# bcp register map
Vendor: Texas Instruments
Peripheral module from a debugger description file (folder Keystone2).
Registers are 32-bit, read-only, no defined reset value unless marked. A register's access mark holds for its fields unless they carry their own. Offsets are as the file gives them; lines under a group give offsets from that group; [hi:lo] are bit positions; {n}, {i} and the like mark numbered series; 'fields as' and 'values as' point back to an identical list; <NAME> marks a mode.

## BCP
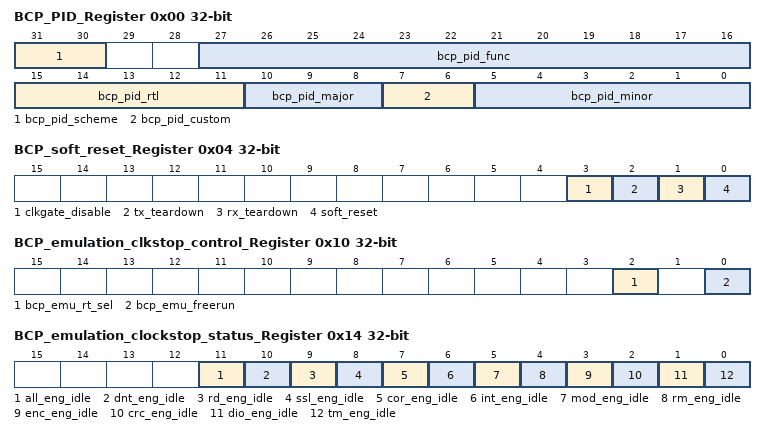
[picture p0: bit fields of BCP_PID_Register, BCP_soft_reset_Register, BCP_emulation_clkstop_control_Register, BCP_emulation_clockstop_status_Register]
0x00 BCP_PID_Register
  [31:30] bcp_pid_scheme, [27:16] bcp_pid_func, [15:11] bcp_pid_rtl, [10:8] bcp_pid_major, [7:6] bcp_pid_custom, [5:0] bcp_pid_minor
0x04 BCP_soft_reset_Register access per field
  [3] clkgate_disable rw — Disables PPB clock gating when set
  [2] tx_teardown rw — TX goes into teardown when set
  [1] rx_teardown rw — RX goes into teardown when set
  [0] soft_reset wo — Resets BCP when set to a 1
0x08 TM_Halt_Ctrl_Register wo — TM halt control register
  [7:0] clear_halt — Clears a halt condition on a channel
0x0C TM_Halt_status_Register
  [7:0] halt_status — Status of halt on a channel
0x10 BCP_emulation_clkstop_control_Register rw — BCP Emulation control register
  [2] bcp_emu_rt_sel — Use dbgsusp_rt when high, dbgsusp when low
  [0] bcp_emu_freerun — Emulation mode is free running when set
0x14 BCP_emulation_clockstop_status_Register — BCP emulation and clockstop status
  [11] all_eng_idle — All engines are idle when bit is set.
  [10] dnt_eng_idle — DNT engine is idle when bit is set.
  [9] rd_eng_idle — RD engine is idle when bit is set.
  [8] ssl_eng_idle — SSL engine is idle when bit is set.
  [7] cor_eng_idle — COR engine is idle when bit is set.
  [6] int_eng_idle — INT engine is idle when bit is set.
  [5] mod_eng_idle — MOD engine is idle when bit is set.
  [4] rm_eng_idle — RM engine is idle when bit is set.
  [3] enc_eng_idle — ENC engine is idle when bit is set.
  [2] crc_eng_idle — CRC engine is idle when bit is set.
  [1] dio_eng_idle — DIO engine is idle when bit is set.
  [0] tm_eng_idle — TM engine is idle when bit is set.
0x18 BCP_datalogger_SW_timestamp_Register rw — BCP Datalogger Software Timestamp
  [31:0] bcp_dlg_sw_timestamp — Datalogger software timestamp.
0x1C BCP_datalogger_HW_timestamp_Register — BCP Datalogger Hardware Timestamp
  [23:0] bcp_dlg_hw_timestamp — Datalogger hardware timestamp.
0x20 BCP_datalogger_HW_timestamp_ctrl_Register rw — BCP Datalogger Hardware Timestamp ctrl
  [0] bcp_dlg_hw_timestamp_run — Datalogger hardware timestamp ctrl.
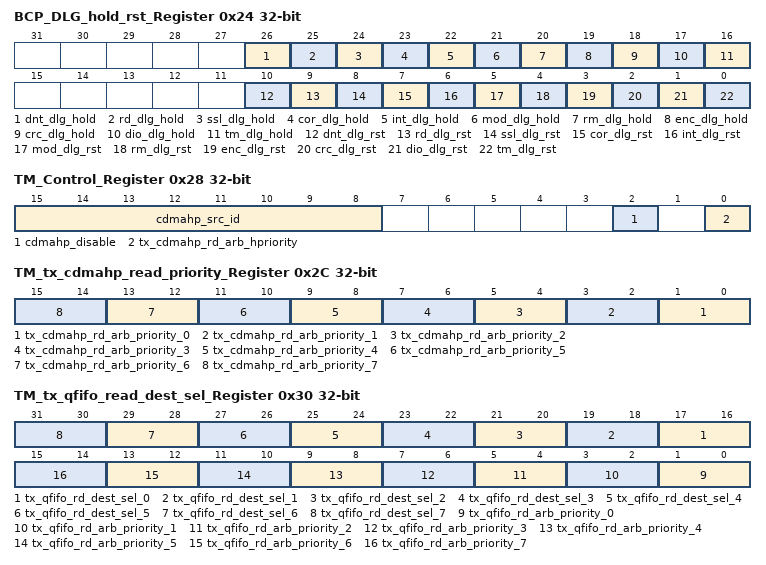
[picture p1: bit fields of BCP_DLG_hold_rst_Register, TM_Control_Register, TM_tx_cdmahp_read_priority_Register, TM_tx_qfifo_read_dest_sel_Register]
0x24 BCP_DLG_hold_rst_Register rw
  [26] dnt_dlg_hold — DNT Data logger put into DLG_HOLD state to hold DLG values when set
  [25] rd_dlg_hold — RD Data logger put into DLG_HOLD state to hold DLG values when set
  [24] ssl_dlg_hold — SSL Data logger put into DLG_HOLD state to hold DLG values when set
  [23] cor_dlg_hold — COR Data logger put into DLG_HOLD state to hold DLG values when set
  [22] int_dlg_hold — INT Data logger put into DLG_HOLD state to hold DLG values when set
  [21] mod_dlg_hold — MOD Data logger put into DLG_HOLD state to hold DLG values when set
  [20] rm_dlg_hold — RM Data logger put into DLG_HOLD state to hold DLG values when set
  [19] enc_dlg_hold — ENC Data logger put into DLG_HOLD state to hold DLG values when set
  [18] crc_dlg_hold — CRC Data logger put into DLG_HOLD state to hold DLG values when set
  [17] dio_dlg_hold — DIO Data logger put into DLG_HOLD state to hold DLG values when set
  [16] tm_dlg_hold — TM Data logger put into DLG_HOLD state to hold DLG values when set
  [10] dnt_dlg_rst — DNT Data logger put into DLG_IDLE state to reset DLG when set
  [9] rd_dlg_rst — RD Data logger put into DLG_IDLE state to reset DLG when set
  [8] ssl_dlg_rst — SSL Data logger put into DLG_IDLE state to reset DLG when set
  [7] cor_dlg_rst — COR Data logger put into DLG_IDLE state to reset DLG when set
  [6] int_dlg_rst — INT Data logger put into DLG_IDLE state to reset DLG when set
  [5] mod_dlg_rst — MOD Data logger put into DLG_IDLE state to reset DLG when set
  [4] rm_dlg_rst — RM Data logger put into DLG_IDLE state to reset DLG when set
  [3] enc_dlg_rst — ENC Data logger put into DLG_IDLE state to reset DLG when set
  [2] crc_dlg_rst — CRC Data logger put into DLG_IDLE state to reset DLG when set
  [1] dio_dlg_rst — DIO Data logger put into DLG_IDLE state to reset DLG when set
  [0] tm_dlg_rst — TM Data logger put into DLG_IDLE state to reset DLG when set
0x28 TM_Control_Register rw
  [15:8] cdmahp_src_id — SRC_ID to insert into RX INFO word 0.
  [2] cdmahp_disable — Disables inputs from the CDMAHP when set high.
  [0] tx_cdmahp_rd_arb_hpriority — Enables increasing tx rd arb priority while that packetis being transferred.
0x2C TM_tx_cdmahp_read_priority_Register rw
  [2n+1:2n] tx_cdmahp_rd_arb_priority_{n} (n=0..7) — Sets CDMAHP read priority for channel {n}.
0x30 TM_tx_qfifo_read_dest_sel_Register rw — TM TX QFIFO read dest sel and arbitrtion priority register
  [2n+17:2n+16] tx_qfifo_rd_dest_sel_{n} (n=0..7) — Sets QFIFO read dest select for channel {n}.
  [2n+1:2n] tx_qfifo_rd_arb_priority_{n} (n=0..7) — Sets QFIFO read arbitration priority for channel {n}.
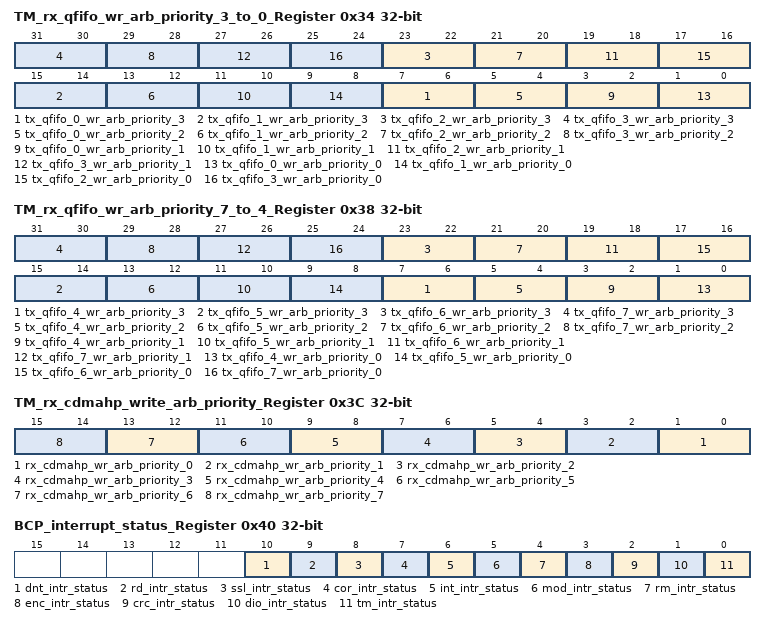
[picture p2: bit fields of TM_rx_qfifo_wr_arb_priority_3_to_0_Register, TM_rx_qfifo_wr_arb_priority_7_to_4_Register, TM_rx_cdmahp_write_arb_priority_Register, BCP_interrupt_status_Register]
0x34 TM_rx_qfifo_wr_arb_priority_3_to_0_Register rw — TM RX QFIFO write arb priority register for channels 0 to 3
  [8n+7:8n+6] tx_qfifo_{n}_wr_arb_priority_3 (n=0..3) — Sets QFIFO {n} wr arb priority from PPB 3.
  [8n+5:8n+4] tx_qfifo_{n}_wr_arb_priority_2 (n=0..3) — Sets QFIFO {n} wr arb priority from PPB 2.
  [8n+3:8n+2] tx_qfifo_{n}_wr_arb_priority_1 (n=0..3) — Sets QFIFO {n} wr arb priority from PPB 1.
  [8n+1:8n] tx_qfifo_{n}_wr_arb_priority_0 (n=0..3) — Sets QFIFO {n} wr arb priority from PPB 0.
0x38 TM_rx_qfifo_wr_arb_priority_7_to_4_Register rw — TM RX QFIFO write arb priority register for channels 7 to 4
  [8n-25:8n-26] tx_qfifo_{n}_wr_arb_priority_3 (n=4..7) — Sets QFIFO {n} wr arb priority from PPB 3.
  [8n-27:8n-28] tx_qfifo_{n}_wr_arb_priority_2 (n=4..7) — Sets QFIFO {n} wr arb priority from PPB 2.
  [8n-29:8n-30] tx_qfifo_{n}_wr_arb_priority_1 (n=4..7) — Sets QFIFO {n} wr arb priority from PPB 1.
  [8n-31:8n-32] tx_qfifo_{n}_wr_arb_priority_0 (n=4..7) — Sets QFIFO {n} wr arb priority from PPB 0.
0x3C TM_rx_cdmahp_write_arb_priority_Register rw
  [2n+1:2n] rx_cdmahp_wr_arb_priority_{n} (n=0..7) — Sets CDMAHP write priority for channel {n}.
0x40 BCP_interrupt_status_Register — (1 of 4, stride 8)
  [10] dnt_intr_status — DNT engine is interrupting when bit is set.
  [9] rd_intr_status — RD engine is interrupting when bit is set.
  [8] ssl_intr_status — SSL engine is interrupting when bit is set.
  [7] cor_intr_status — COR engine is interrupting when bit is set.
  [6] int_intr_status — INT engine is interrupting when bit is set.
  [5] mod_intr_status — MOD engine is interrupting when bit is set.
  [4] rm_intr_status — RM engine is interrupting when bit is set.
  [3] enc_intr_status — ENC engine is interrupting when bit is set.
  [2] crc_intr_status — CRC engine is interrupting when bit is set.
  [1] dio_intr_status — DIO engine is interrupting when bit is set.
  [0] tm_intr_status — TM engine is interrupting when bit is set.
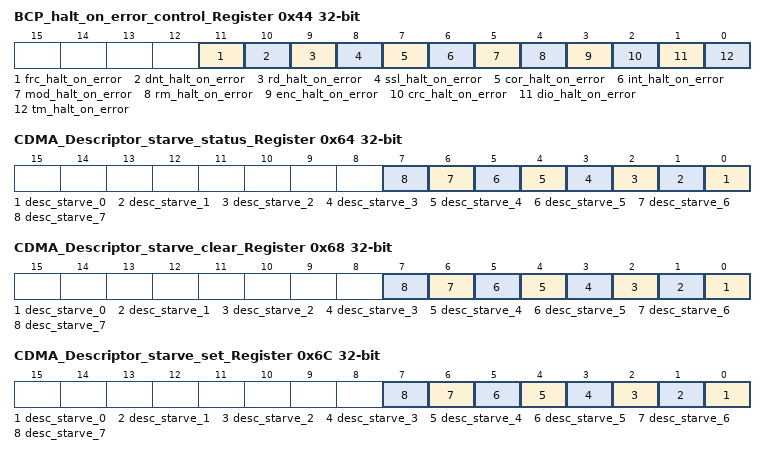
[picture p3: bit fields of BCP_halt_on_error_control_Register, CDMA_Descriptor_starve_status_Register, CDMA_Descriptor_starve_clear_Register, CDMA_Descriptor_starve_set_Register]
0x44 BCP_halt_on_error_control_Register rw — (1 of 4, stride 8)
  [11] frc_halt_on_error — Halts TM.
  [10] dnt_halt_on_error — Halts TM on an error from the DNT engine.
  [9] rd_halt_on_error — Halts TM on an error from the RD engine.
  [8] ssl_halt_on_error — Halts TM on an error from the SSL engine.
  [7] cor_halt_on_error — Halts TM on an error from the COR engine.
  [6] int_halt_on_error — Halts TM on an error from the INT engine.
  [5] mod_halt_on_error — Halts TM on an error from the MOD engine.
  [4] rm_halt_on_error — Halts TM on an error from the RM engine.
  [3] enc_halt_on_error — Halts TM on an error from the ENC engine.
  [2] crc_halt_on_error — Halts TM on an error from the CRC engine.
  [1] dio_halt_on_error — Halts TM on an error from the DIO engine.
  [0] tm_halt_on_error — Halts TM on an error from the TM engine.
0x60 BCP_EOI_Register rw
  [7:0] bcp_eoi — BCP EOI vector for all interrupts.
0x64 CDMA_Descriptor_starve_status_Register — CDMAHP Descriptor Starve status register
  [n] desc_starve_{n} (n=0..7) — CDMAHP descriptor starve indication for queue {n}.
0x68 CDMA_Descriptor_starve_clear_Register wo — CDMAHP Descriptor Starve Clear register
  [n] desc_starve_{n} (n=0..7) — CDMAHP descriptor starve clear for queue {n}.
0x6C CDMA_Descriptor_starve_set_Register wo — CDMAHP Descriptor Starve Set register
  [n] desc_starve_{n} (n=0..7) — CDMAHP descriptor starve set for queue {n}.
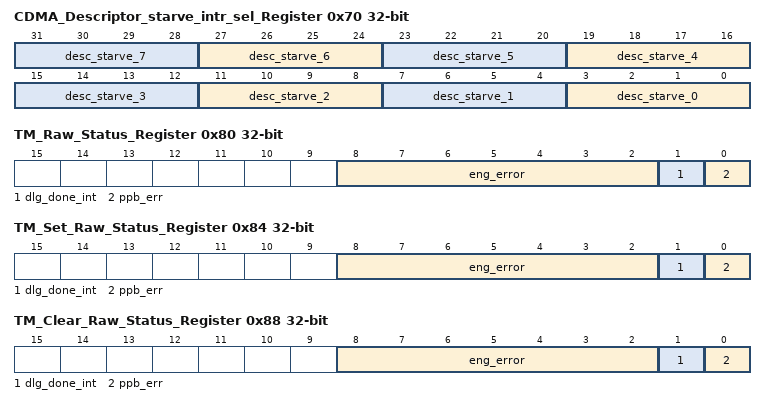
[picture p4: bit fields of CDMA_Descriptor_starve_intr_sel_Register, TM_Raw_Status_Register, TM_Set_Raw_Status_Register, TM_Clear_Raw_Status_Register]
0x70 CDMA_Descriptor_starve_intr_sel_Register rw — CDMAHP Descriptor Starve intr sel register
  [4n+3:4n] desc_starve_{n} (n=0..7) — CDMAHP descriptor starve interrupt CPU selection for queue {n}.
0x80 TM_Raw_Status_Register — (1 of 4, stride 28)
  [8:2] eng_error
  [1] dlg_done_int — data logger Error.
  [0] ppb_err — PPB Error.
0x84 TM_Set_Raw_Status_Register wo — (1 of 4, stride 28)
  [8:2] eng_error — Set Engine errors.
  [1] dlg_done_int — Set Data logger done has ocurred.
  [0] ppb_err — Set PPB Error.
0x88 TM_Clear_Raw_Status_Register wo — (1 of 4, stride 28)
  [8:2] eng_error — Clear Engine errors.
  [1] dlg_done_int — Clear Data logger done has ocurred.
  [0] ppb_err — Clear PPB Error.
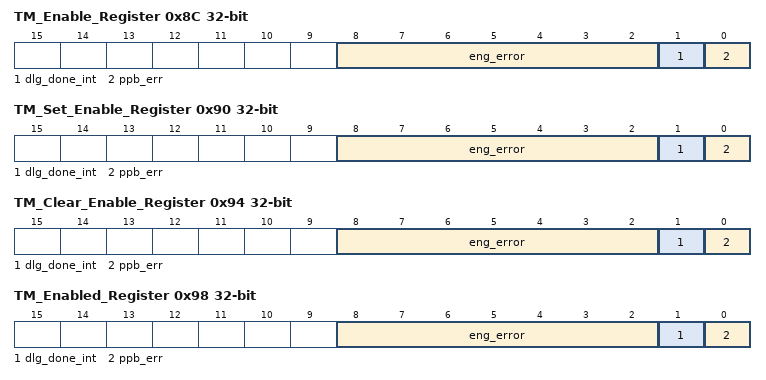
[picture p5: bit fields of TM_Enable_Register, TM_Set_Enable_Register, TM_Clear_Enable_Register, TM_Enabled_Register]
0x8C TM_Enable_Register — (1 of 4, stride 28)
  [8:2] eng_error — Set Engine errors.
  [1] dlg_done_int — Set Data logger done has ocurred.
  [0] ppb_err — Enable for PPB Error.
0x90 TM_Set_Enable_Register wo — (1 of 4, stride 28)
  [8:2] eng_error — Set Enable Engine errors.
  [1] dlg_done_int — Set Enable Data logger done has ocurred.
  [0] ppb_err — Set Enable PPB Error.
0x94 TM_Clear_Enable_Register wo — (1 of 4, stride 28)
  [8:2] eng_error — Clear Enable Engine errors.
  [1] dlg_done_int — Clear Enable Data logger done has ocurred.
  [0] ppb_err — Clear Enable PPB Error.
0x98 TM_Enabled_Register — (1 of 4, stride 28)
  [8:2] eng_error — Set Engine errors.
  [1] dlg_done_int — Set Data logger done has ocurred.
  [0] ppb_err — Enabled PPB Error.
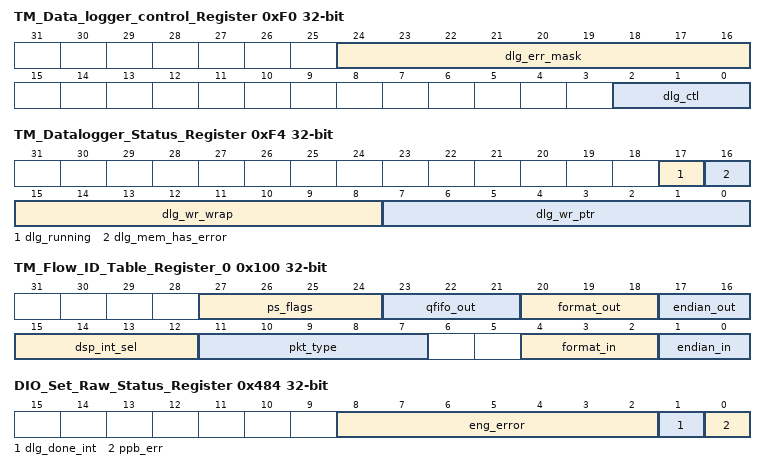
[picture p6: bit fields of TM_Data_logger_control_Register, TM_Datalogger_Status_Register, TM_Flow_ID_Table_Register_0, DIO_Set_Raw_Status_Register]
0xF0 TM_Data_logger_control_Register rw — Data logger control Register
  [24:16] dlg_err_mask — Masks off the corresponding error field to the DLG when set.
  [2:0] dlg_ctl — Selects the mode that DLG is running. Shown in the datalogger write control section.
0xF4 TM_Datalogger_Status_Register — Datalogger Status Register
  [17] dlg_running — Set while capturing data.
  [16] dlg_mem_has_error — At least one error is stored in memory.
  [15:8] dlg_wr_wrap — Number of times writing to memory wrapped to 0. Stops at FF
  [7:0] dlg_wr_ptr — Read only passing the current RAM write pointer.
0xF8 TM_Global_Header_Register
  [31:0] global_hdr — Read only passing the current value of the Global Header field.
0x100 TM_Flow_ID_Table_Register_0 rw — (1 of 64, stride 4)
  [27:24] ps_flags — PS_FLAGS to set for RX INFO word 0.
  [23:21] qfifo_out — Selects which QFIFO in the RX the PPB sends the data through.
  [20:18] format_out — Format going out of the RX for payload.
  [17:16] endian_out — Endian going out of the RX for payload.
  [15:12] dsp_int_sel — Interrupt Select for which DSP to interrupt on errors.
  [11:7] pkt_type — Packet type for RX INFO word 0.
  [4:2] format_in — format coming in to TX for payload.
  [1:0] endian_in — Endian coming in to TX for payload
0x400 DIO_Vbusm_Priority rw — BCP DIO Vbusm priority Register
  [2:0] dio_vbusm_priority — Controls priority outputs from the dio core.0x0 is highest priority, 0x7 is lowest priority
0x480 DIO_Raw_Status_Register — (1 of 4, stride 28)
  [7:0] ppb_err — PPB Error.
0x484 DIO_Set_Raw_Status_Register wo — (1 of 4, stride 28)
  fields as TM_Set_Raw_Status_Register
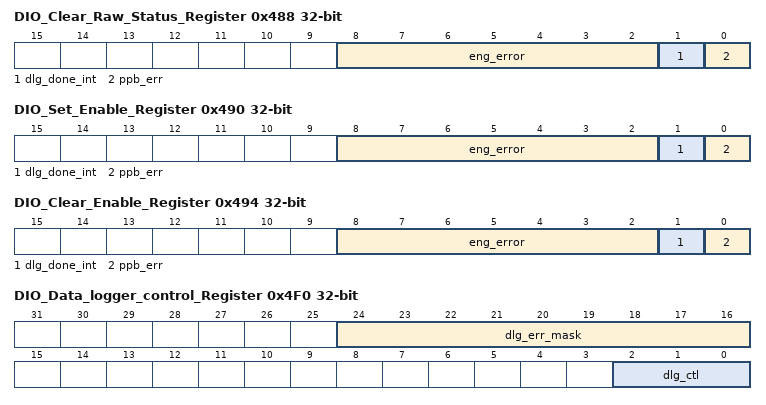
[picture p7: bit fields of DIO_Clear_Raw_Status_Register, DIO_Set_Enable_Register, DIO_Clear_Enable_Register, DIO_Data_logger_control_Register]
0x488 DIO_Clear_Raw_Status_Register wo — (1 of 4, stride 28)
  fields as TM_Clear_Raw_Status_Register
0x48C DIO_Enable_Register — (1 of 4, stride 28)
  [7:0] ppb_err — Enable for PPB Error.
0x490 DIO_Set_Enable_Register wo — (1 of 4, stride 28)
  fields as TM_Set_Enable_Register
0x494 DIO_Clear_Enable_Register wo — (1 of 4, stride 28)
  fields as TM_Clear_Enable_Register
0x498 DIO_Enabled_Register — (1 of 4, stride 28)
  [7:0] ppb_err — Enabled PPB Error.
0x4F0 DIO_Data_logger_control_Register rw — Data logger control Register
  fields as TM_Data_logger_control_Register
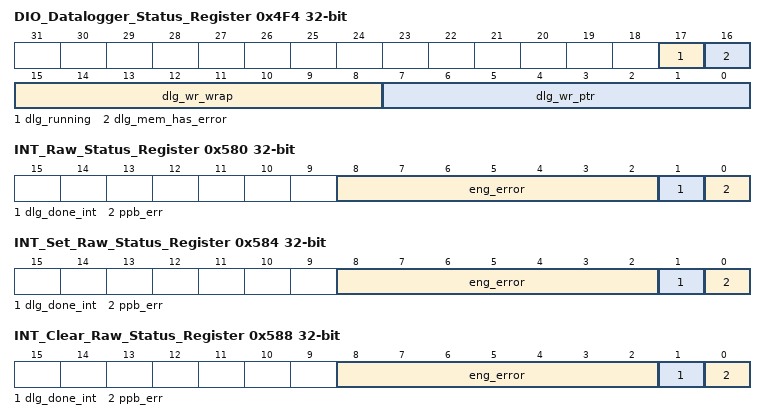
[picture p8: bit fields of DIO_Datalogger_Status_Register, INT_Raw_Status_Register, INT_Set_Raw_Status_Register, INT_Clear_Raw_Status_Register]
0x4F4 DIO_Datalogger_Status_Register — Datalogger Status Register
  fields as TM_Datalogger_Status_Register
0x4F8 DIO_Global_Header_Register — Submodule Global Header Register
  fields as TM_Global_Header_Register
0x580 INT_Raw_Status_Register — (1 of 4, stride 28)
  [8:2] eng_error — Engine errors.
  [1] dlg_done_int — Data logger done has ocurred.
  [0] ppb_err — PPB Error.
0x584 INT_Set_Raw_Status_Register wo — (1 of 4, stride 28)
  fields as TM_Set_Raw_Status_Register
0x588 INT_Clear_Raw_Status_Register wo — (1 of 4, stride 28)
  fields as TM_Clear_Raw_Status_Register
0x58C INT_Enable_Register — (1 of 4, stride 28)
  [8:2] eng_error — Enable for Engine errors.
  [1] dlg_done_int — Enable for Data logger done has ocurred.
  [7:0] ppb_err — Enable for PPB Error.
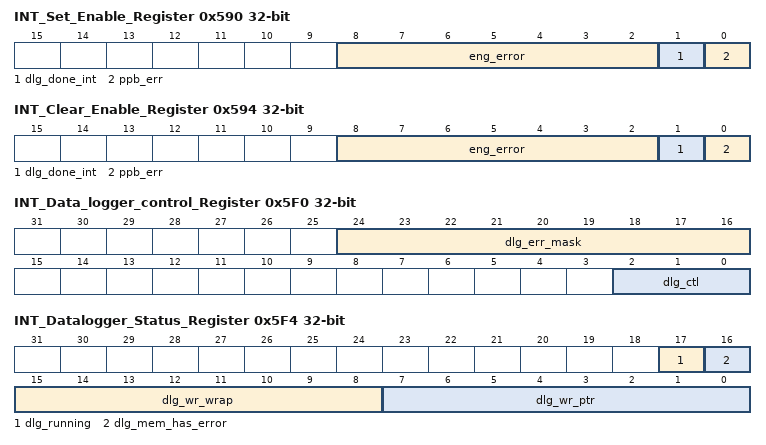
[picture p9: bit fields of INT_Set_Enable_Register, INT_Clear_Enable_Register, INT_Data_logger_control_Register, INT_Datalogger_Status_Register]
0x590 INT_Set_Enable_Register wo — (1 of 4, stride 28)
  fields as TM_Set_Enable_Register
0x594 INT_Clear_Enable_Register wo — (1 of 4, stride 28)
  fields as TM_Clear_Enable_Register
0x598 INT_Enabled_Register — (1 of 4, stride 28)
  [8:2] eng_error — Enabled Engine errors.
  [7:0] ppb_err — Enabled PPB Error.
0x5F0 INT_Data_logger_control_Register rw — Data logger control Register
  fields as TM_Data_logger_control_Register
0x5F4 INT_Datalogger_Status_Register — Datalogger Status Register
  fields as TM_Datalogger_Status_Register
0x5F8 INT_Global_Header_Register — Submodule Global Header Register
  fields as TM_Global_Header_Register
0x680 RM_Raw_Status_Register — (1 of 4, stride 28)
  [7:0] ppb_err — PPB Error.
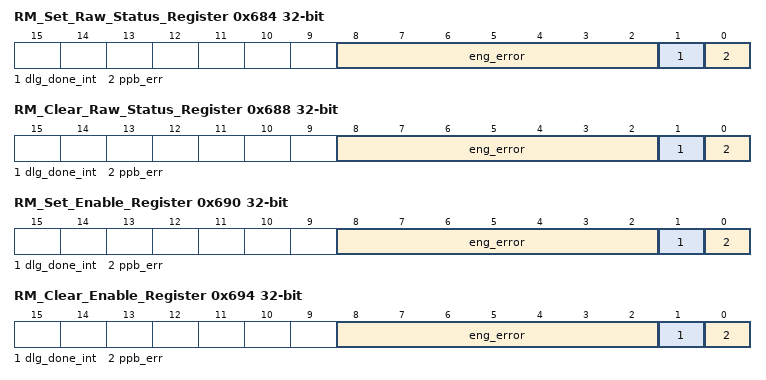
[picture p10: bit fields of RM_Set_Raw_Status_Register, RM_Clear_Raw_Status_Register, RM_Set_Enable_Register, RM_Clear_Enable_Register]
0x684 RM_Set_Raw_Status_Register wo — (1 of 4, stride 28)
  fields as TM_Set_Raw_Status_Register
0x688 RM_Clear_Raw_Status_Register wo — (1 of 4, stride 28)
  fields as TM_Clear_Raw_Status_Register
0x68C RM_Enable_Register — (1 of 4, stride 28)
  [7:0] ppb_err — Enable for PPB Error.
0x690 RM_Set_Enable_Register wo — (1 of 4, stride 28)
  fields as TM_Set_Enable_Register
0x694 RM_Clear_Enable_Register wo — (1 of 4, stride 28)
  fields as TM_Clear_Enable_Register
0x698 RM_Enabled_Register — (1 of 4, stride 28)
  [7:0] ppb_err — Enabled PPB Error.
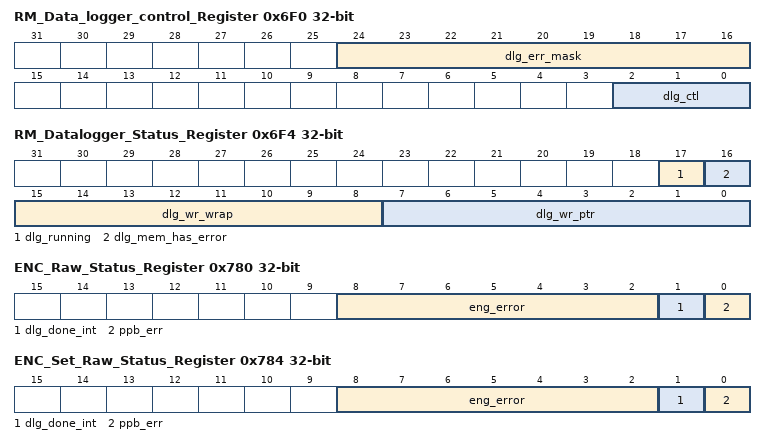
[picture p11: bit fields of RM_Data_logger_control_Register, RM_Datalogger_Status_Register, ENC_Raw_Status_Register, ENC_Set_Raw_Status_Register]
0x6F0 RM_Data_logger_control_Register rw — Data logger control Register
  fields as TM_Data_logger_control_Register
0x6F4 RM_Datalogger_Status_Register — Datalogger Status Register
  fields as TM_Datalogger_Status_Register
0x6F8 RM_Global_Header_Register
  fields as TM_Global_Header_Register
{0x6FC+4i} POLY_COEF{i} rw (i=1..3) — polynomial coefficient set {i}
  [23:0] POLYCOEF{i} — polynomial coefficients in 32-bit word as described in the specification (LSB Justified)
{0x70C+0x10*i} SCR_INIT_{i} rw (i=0..2) — scrambler initialization set {i}
  [31:16] SCRINIT — Scrambler Initialization (MSB justified)
{0x710+0x10*i} SCR_POLY_{i} rw (i=0..2) — scrambler Polynomial set {i}
  [31:16] SCRPOLY — Scrambler Polynomial (MSB justified)
0x714 CRC24_INIT_0 rw — CRC-24 Initialization set 0
  [31:8] CRC24INIT — CRC 24 Initialization (MSB justified)
0x718 CRC24_POLY_0 rw — CRC-24 Polynomial set 0
  [31:8] CRC24POLY — CRC 24 Polynomial (MSB justified)
0x724 CRC16_INIT_1 rw — CRC-16 Initialization set 1
  [31:16] CRC16INIT — CRC 16 Initialization (MSB justified)
0x728 CRC16_POLY_1 rw — CRC-16 Polynomial set 1
  [31:16] CRC16POLY — CRC 16 Polynomial (MSB justified)
0x780 ENC_Raw_Status_Register — (1 of 4, stride 28)
  fields as INT_Raw_Status_Register
0x784 ENC_Set_Raw_Status_Register wo — (1 of 4, stride 28)
  fields as TM_Set_Raw_Status_Register
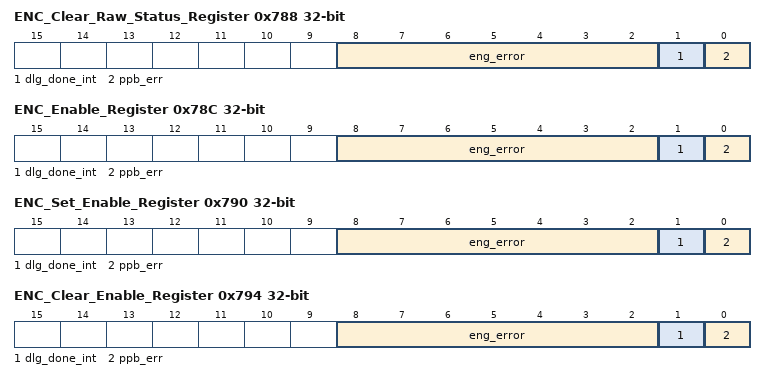
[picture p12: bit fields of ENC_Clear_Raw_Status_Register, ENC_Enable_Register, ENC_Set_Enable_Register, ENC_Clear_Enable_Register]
0x788 ENC_Clear_Raw_Status_Register wo — (1 of 4, stride 28)
  fields as TM_Clear_Raw_Status_Register
0x78C ENC_Enable_Register — (1 of 4, stride 28)
  [8:2] eng_error — Enable for Engine errors.
  [1] dlg_done_int — Enable for Data logger done .
  [0] ppb_err — Enable for PPB Error.
0x790 ENC_Set_Enable_Register wo — (1 of 4, stride 28)
  fields as TM_Set_Enable_Register
0x794 ENC_Clear_Enable_Register wo — (1 of 4, stride 28)
  fields as TM_Clear_Enable_Register
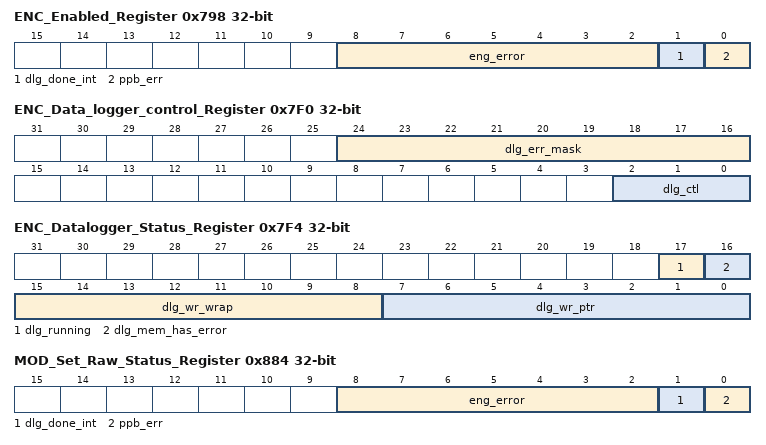
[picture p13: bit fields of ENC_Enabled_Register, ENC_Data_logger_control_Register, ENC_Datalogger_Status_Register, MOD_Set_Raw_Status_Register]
0x798 ENC_Enabled_Register — (1 of 4, stride 28)
  [8:2] eng_error — Enabled Engine errors.
  [1] dlg_done_int — Enabled Data logger done.
  [0] ppb_err — Enabled PPB Error.
0x7F0 ENC_Data_logger_control_Register rw — Data logger control Register
  fields as TM_Data_logger_control_Register
0x7F4 ENC_Datalogger_Status_Register — Datalogger Status Register
  fields as TM_Datalogger_Status_Register
0x7F8 ENC_Global_Header_Register — Submodule Global Header Register
  fields as TM_Global_Header_Register
0x880 MOD_Raw_Status_Register — (1 of 4, stride 28)
  [7:0] ppb_err — PPB Error.
0x884 MOD_Set_Raw_Status_Register wo — (1 of 4, stride 28)
  fields as TM_Set_Raw_Status_Register
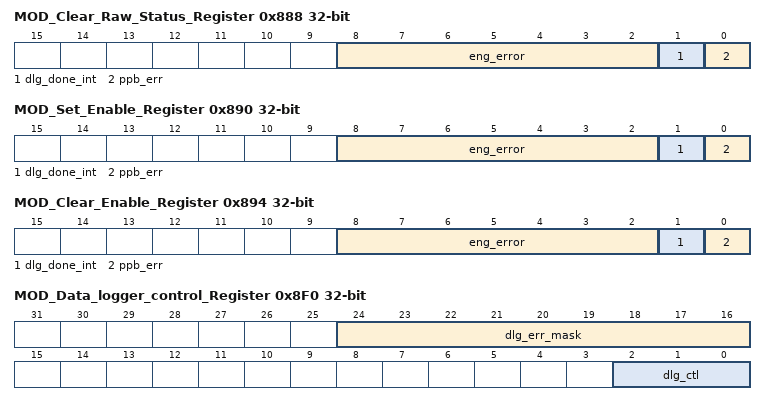
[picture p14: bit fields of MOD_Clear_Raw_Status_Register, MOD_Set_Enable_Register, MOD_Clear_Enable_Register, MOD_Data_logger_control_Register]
0x888 MOD_Clear_Raw_Status_Register wo — (1 of 4, stride 28)
  fields as TM_Clear_Raw_Status_Register
0x88C MOD_Enable_Register — (1 of 4, stride 28)
  [7:0] ppb_err — Enable for PPB Error.
0x890 MOD_Set_Enable_Register wo — (1 of 4, stride 28)
  fields as TM_Set_Enable_Register
0x894 MOD_Clear_Enable_Register wo — (1 of 4, stride 28)
  fields as TM_Clear_Enable_Register
0x898 MOD_Enabled_Register — (1 of 4, stride 28)
  [7:0] ppb_err — Enabled PPB Error.
0x8F0 MOD_Data_logger_control_Register rw — Data logger control Register
  fields as TM_Data_logger_control_Register
0x8F4 MOD_Datalogger_Status_Register — Datalogger Status Register
  fields as TM_Datalogger_Status_Register
0x8F8 MOD_Global_Header_Register — Submodule Global Header Register
  fields as TM_Global_Header_Register
0x980 DNT_Raw_Status_Register — (1 of 4, stride 28)
  fields as INT_Raw_Status_Register
0x984 DNT_Set_Raw_Status_Register wo — (1 of 4, stride 28)
  fields as TM_Set_Raw_Status_Register
0x988 DNT_Clear_Raw_Status_Register wo — (1 of 4, stride 28)
  fields as TM_Clear_Raw_Status_Register
0x98C DNT_Enable_Register — (1 of 4, stride 28)
  [8:2] eng_error — Enable for Engine errors.
  [1] dlg_done_int — Enable for Data logger done has ocurred.
  [0] ppb_err — Enable for PPB Error.
0x990 DNT_Set_Enable_Register wo — (1 of 4, stride 28)
  fields as TM_Set_Enable_Register
0x994 DNT_Clear_Enable_Register wo — (1 of 4, stride 28)
  fields as TM_Clear_Enable_Register
0x998 DNT_Enabled_Register — (1 of 4, stride 28)
  [8:2] eng_error — Enabled Engine errors.
  [1] dlg_done_int — Enabled Data logger done has ocurred.
  [0] ppb_err — Enabled PPB Error.
0x9F0 DNT_Data_logger_control_Register rw — Data logger control Register
  fields as TM_Data_logger_control_Register
0x9F4 DNT_Datalogger_Status_Register — Datalogger Status Register
  fields as TM_Datalogger_Status_Register
0x9F8 DNT_Global_Header_Register — Submodule Global Header Register
  fields as TM_Global_Header_Register
0xA80 SSL_Raw_Status_Register — (1 of 4, stride 28)
  [7:0] ppb_err — PPB Error.
0xA84 SSL_Set_Raw_Status_Register wo — (1 of 4, stride 28)
  fields as TM_Set_Raw_Status_Register
0xA88 SSL_Clear_Raw_Status_Register wo — (1 of 4, stride 28)
  fields as TM_Clear_Raw_Status_Register
0xA8C SSL_Enable_Register — (1 of 4, stride 28)
  [7:0] ppb_err — Enable for PPB Error.
0xA90 SSL_Set_Enable_Register wo — (1 of 4, stride 28)
  fields as TM_Set_Enable_Register
0xA94 SSL_Clear_Enable_Register wo — (1 of 4, stride 28)
  fields as TM_Clear_Enable_Register
0xA98 SSL_Enabled_Register — (1 of 4, stride 28)
  [7:0] ppb_err — Enabled PPB Error.
0xAF0 SSL_Data_logger_control_Register rw — Data logger control Register
  fields as TM_Data_logger_control_Register
0xAF4 SSL_Datalogger_Status_Register — Datalogger Status Register
  fields as TM_Datalogger_Status_Register
0xAF8 SSL_Global_Header_Register — Submodule Global Header Register
  fields as TM_Global_Header_Register
0xB00 RD_Vbusm_Priority rw — BCP RD Vbusm priority Register
  [2:0] dio_vbusm_priority — Controls priority outputs from the dio core.
0xB80 RD_Raw_Status_Register — (1 of 4, stride 28)
  fields as TM_Raw_Status_Register
0xB84 RD_Set_Raw_Status_Register wo — (1 of 4, stride 28)
  fields as TM_Set_Raw_Status_Register
0xB88 RD_Clear_Raw_Status_Register wo — (1 of 4, stride 28)
  fields as TM_Clear_Raw_Status_Register
0xB8C RD_Enable_Register — (1 of 4, stride 28)
  fields as TM_Enable_Register
0xB90 RD_Set_Enable_Register wo — (1 of 4, stride 28)
  fields as TM_Set_Enable_Register
0xB94 RD_Clear_Enable_Register wo — (1 of 4, stride 28)
  fields as TM_Clear_Enable_Register
0xB98 RD_Enabled_Register — (1 of 4, stride 28)
  fields as TM_Enabled_Register
0xBF0 RD_Data_logger_control_Register rw — Data logger control Register
  fields as TM_Data_logger_control_Register
0xBF4 RD_Datalogger_Status_Register — Datalogger Status Register
  fields as TM_Datalogger_Status_Register
0xBF8 RD_Global_Header_Register
  fields as TM_Global_Header_Register
{0xC00+4i} M{i} rw (i=0..12)
  [23:0] MOD_EN — column {i} of the Reed-Muller table; lsb is row 0
0xC34 control_register rw
  [7:6] QPSK_MAPPING_C2k10_C2k0 — +1 = 00, +j = 01,
  [5:4] QPSK_MAPPING_C2k10_C2k1 — +1 = 00, +j = 01,
  [3:2] QPSK_MAPPING_C2k11_C2k0 — +1 = 00, +j = 01,
  [1:0] QPSK_MAPPING_C2k11_C2k1 — +1 = 00, +j = 01,
0xC80 COR_Raw_Status_Register — (1 of 4, stride 28)
  [8] cor_E6_UNUSED — COR: Error code 6 not used.
  [7] cor_E5_DSPRD_DATA_SIZE_ERR — DSPRD: Input data size incorrect.
  [6] cor_E4_COR_DATA_SHORT — COR: Insufficient input data.
  [5] cor_E3_COR_NR_ZERO — COR: Num Ant EQ zero.
  [4] cor_E2_COR_NR_GT_8 — COR: Num Ant GT 8.
  [3] cor_E1_COR_A_ZERO — COR: A EQ zero.
  [2] cor_E0_COR_A_GT_13 — COR: A GT 13.
  [1] dlg_done_int — data logger Error.
  [0] ppb_err — PPB Error.
0xC84 COR_Set_Raw_Status_Register wo — (1 of 4, stride 28)
  [8] cor_E6_UNUSED — COR: Set Err: Error code 6 not used.
  [7] cor_E5_DSPRD_DATA_SIZE_ERR — DSPRD: Set Err: Input data size incorrect.
  [6] cor_E4_COR_DATA_SHORT — COR: Set Err: Insufficient input data.
  [5] cor_E3_COR_NR_ZERO — COR: Set Err: Num Ant EQ zero.
  [4] cor_E2_COR_NR_GT_8 — COR: Set Err: Num Ant GT 8.
  [3] cor_E1_COR_A_ZERO — COR: Set Err: A EQ zero.
  [2] cor_E0_COR_A_GT_13 — COR: Set Err: A GT 13.
  [1] dlg_done_int — Set Data logger done has ocurred.
  [0] ppb_err — Set PPB Error.
0xC88 COR_Clear_Raw_Status_Register wo — (1 of 4, stride 28)
  [8] cor_E6_UNUSED — COR: Clr Err: Error code 6 not used.
  [7] cor_E5_DSPRD_DATA_SIZE_ERR — DSPRD: Clr Err: Input data size incorrect.
  [6] cor_E4_COR_DATA_SHORT — COR: Clr Err: Insufficient input data.
  [5] cor_E3_COR_NR_ZERO — COR: Clr Err: Num Ant EQ zero.
  [4] cor_E2_COR_NR_GT_8 — COR: Clr Err: Num Ant GT 8.
  [3] cor_E1_COR_A_ZERO — COR: Clr Err: A EQ zero.
  [2] cor_E0_COR_A_GT_13 — COR: Clr Err: A GT 13.
  [1] dlg_done_int — Clear Data logger done has ocurred.
  [0] ppb_err — Clear PPB Error.
0xC8C COR_Enable_Register — (1 of 4, stride 28)
  [8] cor_E6_UNUSED — COR: En for Int: Error code 6 not used.
  [7] cor_E5_DSPRD_DATA_SIZE_ERR — DSPRD: En for Int: Input data size incorrect.
  [6] cor_E4_COR_DATA_SHORT — COR: En for Int: Insufficient input data.
  [5] cor_E3_COR_NR_ZERO — COR: En for Int: Num Ant EQ zero.
  [4] cor_E2_COR_NR_GT_8 — COR: En for Int: Num Ant GT 8.
  [3] cor_E1_COR_A_ZERO — COR: En for Int: A EQ zero.
  [2] cor_E0_COR_A_GT_13 — COR: En for Int: A GT 13.
  [1] dlg_done_int — Enable for Data logger done has ocurred.
  [0] ppb_err — Enable for PPB Error.
0xC90 COR_Set_Enable_Register wo — (1 of 4, stride 28)
  [8] cor_E6_UNUSED — COR: Set En Err: Error code 6 not used.
  [7] cor_E5_DSPRD_DATA_SIZE_ERR — DSPRD: Set En Err: Input data size incorrect.
  [6] cor_E4_COR_DATA_SHORT — COR: Set En Err: Insufficient input data.
  [5] cor_E3_COR_NR_ZERO — COR: Set En Err: Num Ant EQ zero.
  [4] cor_E2_COR_NR_GT_8 — COR: Set En Err: Num Ant GT 8.
  [3] cor_E1_COR_A_ZERO — COR: Set En Err: A EQ zero.
  [2] cor_E0_COR_A_GT_13 — COR: Set En Err: A GT 13.
  [1] dlg_done_int — Set Enable Data logger done has ocurred.
  [0] ppb_err — Set Enable PPB Error.
0xC94 COR_Clear_Enable_Register wo — (1 of 4, stride 28)
  [8] cor_E6_UNUSED — COR: Clr En for Int: Error code 6 not used.
  [7] cor_E5_DSPRD_DATA_SIZE_ERR — DSPRD: Clr En for Int: Input data size incorrect.
  [6] cor_E4_COR_DATA_SHORT — COR: Clr En for Int: Insufficient input data.
  [5] cor_E3_COR_NR_ZERO — COR: Clr En for Int: Num Ant EQ zero.
  [4] cor_E2_COR_NR_GT_8 — COR: Clr En for Int: Num Ant GT 8.
  [3] cor_E1_COR_A_ZERO — COR: Clr En for Int: A EQ zero.
  [2] cor_E0_COR_A_GT_13 — COR: Clr En for Int: A GT 13.
  [1] dlg_done_int — Clear Enable Data logger done has ocurred.
  [0] ppb_err — Clear Enable PPB Error.
0xC98 COR_Enabled_Register — (1 of 4, stride 28)
  [8] cor_E6_UNUSED — COR: Enabled Int: Error code 6 not used.
  [7] cor_E5_DSPRD_DATA_SIZE_ERR — DSPRD: Enabled Int: Input data size incorrect.
  [6] cor_E4_COR_DATA_SHORT — COR: Enabled Int: Insufficient input data.
  [5] cor_E3_COR_NR_ZERO — COR: Enabled Int: Num Ant EQ zero.
  [4] cor_E2_COR_NR_GT_8 — COR: Enabled Int: Num Ant GT 8.
  [3] cor_E1_COR_A_ZERO — COR: Enabled Int: A EQ zero.
  [2] cor_E0_COR_A_GT_13 — COR: Enabled Int: A GT 13.
  [1] dlg_done_int — Enable Data logger done has ocurred.
  [0] ppb_err — Enabled PPB Error.
0xCF0 COR_Data_logger_control_Register rw — Data logger control Register
  fields as TM_Data_logger_control_Register
0xCF4 COR_Datalogger_Status_Register — Datalogger Status Register
  fields as TM_Datalogger_Status_Register
0xCF8 COR_Global_Header_Register — Submodule Global Header Register
  fields as TM_Global_Header_Register
0xD00 CRC8_POLY rw — CRC polynomial
  [31:24] CRC8_POLY
0xD04 CRC12_POLY rw — CRC polynomial
  [31:20] CRC12_POLY
0xD08 CRC16_POLY rw — CRC polynomial
  [31:16] CRC16_POLY
0xD0C CRC16W_POLY rw — CRC polynomial
  [31:16] CRC16W_POLY
0xD10 CRC24A_POLY rw — CRC polynomial
  [31:8] CRC24A_POLY
0xD14 CRC24B_POLY rw — CRC polynomial
  [31:8] CRC24B_POLY
0xD18 CRC32_POLY rw — CRC polynomial
  [31:0] CRC23_POLY
0xD1C CRC_INIT rw
  [6] CRC32_INIT_VAL — CRC init 1 = allones 0 = all zeros
  [5] CRC24B_INIT_VAL — CRC init 1 = allones 0 = all zeros
  [4] CRC24A_INIT_VAL — CRC init 1 = allones 0 = all zeros
  [3] CRC16W_INIT_VAL — CRC init 1 = allones 0 = all zeros
  [2] CRC16_INIT_VAL — CRC init 1 = allones 0 = all zeros
  [1] CRC12_INIT_VAL — CRC init 1 = allones 0 = all zeros
  [0] CRC8_INIT_VAL — CRC init 1 = allones 0 = all zeros
0xD20 SCR_POLY1 rw — Scrambler polynomial 1
0xD24 SCR_POLY2 rw — Scrambler polynomial 2
0xD80 CRC_Raw_Status_Register — (1 of 4, stride 28)
  fields as INT_Raw_Status_Register
0xD84 CRC_Set_Raw_Status_Register wo — (1 of 4, stride 28)
  fields as TM_Set_Raw_Status_Register
0xD88 CRC_Clear_Raw_Status_Register wo — (1 of 4, stride 28)
  fields as TM_Clear_Raw_Status_Register
0xD8C CRC_Enable_Register — (1 of 4, stride 28)
  [8:2] eng_error — Engine errors.
  [1] dlg_done_int — Data logger done has ocurred.
  [0] ppb_err — Enable for PPB Error.
0xD90 CRC_Set_Enable_Register wo — (1 of 4, stride 28)
  fields as TM_Set_Enable_Register
0xD94 CRC_Clear_Enable_Register wo — (1 of 4, stride 28)
  fields as TM_Clear_Enable_Register
0xD98 CRC_Enabled_Register — (1 of 4, stride 28)
  fields as DNT_Enabled_Register
0xDF0 CRC_Data_logger_control_Register rw — Data logger control Register
  fields as TM_Data_logger_control_Register
0xDF4 CRC_Datalogger_Status_Register — Datalogger Status Register
  fields as TM_Datalogger_Status_Register
0xDF8 CRC_Global_Header_Register — Submodule Global Header Register
  fields as TM_Global_Header_Register
0x2000 TM_Data_logger_Global_Header_Field — (1 of 256, stride 16)
  [31:0] global_hdr — Current value of the Global Header field.
0x2004 TM_Data_logger_TM_Software_Timestamp — (1 of 256, stride 16)
  [31:0] tm_sw_timestamp — Current value of the TM software timestamp.
0x2008 TM_Data_logger_HW_Timestamp_and_Engine_Errors — (1 of 256, stride 16)
  [31:24] eng_err — Current value of the tm engine errors.
  [23:0] tm_hw_timestamp — Current value of the TM Hardware Timestamp.
0x3000 DIO_Data_logger_Global_Header_Field — (1 of 256, stride 16)
  [31:0] global_hdr — Current value of the Global Header field.
0x3004 DIO_Data_logger_TM_Software_Timestamp — (1 of 256, stride 16)
  [31:0] tm_sw_timestamp — Current value of the TM software timestamp.
0x3008 DIO_Data_logger_HW_Timestamp_and_Engine_Errors — (1 of 256, stride 16)
  [31:24] eng_err — Current value of the DIO engine errors.
  [23:0] tm_hw_timestamp — Current value of the TM Hardware Timestamp.
0x4000 INT_Data_logger_Global_Header_Field — (1 of 256, stride 16)
  [31:0] global_hdr — Current value of the Global Header field.
0x4004 INT_Data_logger_TM_Software_Timestamp — (1 of 256, stride 16)
  [31:0] tm_sw_timestamp — Current value of the TM software timestamp.
0x4008 INT_Data_logger_HW_Timestamp_and_Engine_Errors — (1 of 256, stride 16)
  [31:24] eng_err — Current value of the INT engine errors.
  [23:0] tm_hw_timestamp — Current value of the TM Hardware Timestamp.
0x5000 RM_Data_logger_Global_Header_Field — (1 of 256, stride 16)
  [31:0] global_hdr — Current value of the Global Header field.
0x5004 RM_Data_logger_TM_Software_Timestamp — (1 of 256, stride 16)
  [31:0] tm_sw_timestamp — Current value of the TM software timestamp.
0x5008 RM_Data_logger_HW_Timestamp_and_Engine_Errors — (1 of 256, stride 16)
  [31:24] eng_err — Current value of the RM engine errors.
  [23:0] tm_hw_timestamp — Current value of the TM Hardware Timestamp.
0x6000 ENC_Data_logger_Global_Header_Field — (1 of 256, stride 16)
  [31:0] global_hdr — Current value of the Global Header field.
0x6004 ENC_Data_logger_TM_Software_Timestamp — (1 of 256, stride 16)
  [31:0] tm_sw_timestamp — Current value of the TM software timestamp.
0x6008 ENC_Data_logger_HW_Timestamp_and_Engine_Errors — (1 of 256, stride 16)
  [31:24] eng_err — Current value of the ENC engine errors.
  [23:0] tm_hw_timestamp — Current value of the TM Hardware Timestamp.
0x7000 MOD_Data_logger_Global_Header_Field — (1 of 256, stride 16)
  [31:0] global_hdr — Current value of the Global Header field.
0x7004 MOD_Data_logger_TM_Software_Timestamp — (1 of 256, stride 16)
  [31:0] tm_sw_timestamp — Current value of the TM software timestamp.
0x7008 MOD_Data_logger_HW_Timestamp_and_Engine_Errors — (1 of 256, stride 16)
  [31:24] eng_err — Current value of the MOD engine errors.
  [23:0] tm_hw_timestamp — Current value of the TM Hardware Timestamp.
0x8000 DNT_Data_logger_Global_Header_Field — (1 of 256, stride 16)
  [31:0] global_hdr — Current value of the Global Header field.
0x8004 DNT_Data_logger_TM_Software_Timestamp — (1 of 256, stride 16)
  [31:0] tm_sw_timestamp — Current value of the TM software timestamp.
0x8008 DNT_Data_logger_HW_Timestamp_and_Engine_Errors — (1 of 256, stride 16)
  [31:24] eng_err — Current value of the DNT engine errors.
  [23:0] tm_hw_timestamp — Current value of the TM Hardware Timestamp.
0x9000 SSL_Data_logger_Global_Header_Field — (1 of 256, stride 16)
  [31:0] global_hdr — Current value of the Global Header field.
0x9004 SSL_Data_logger_TM_Software_Timestamp — (1 of 256, stride 16)
  [31:0] tm_sw_timestamp — Current value of the TM software timestamp.
0x9008 SSL_Data_logger_HW_Timestamp_and_Engine_Errors — (1 of 256, stride 16)
  [31:24] eng_err — Current value of the SSL engine errors.
  [23:0] tm_hw_timestamp — Current value of the TM Hardware Timestamp.
0xA000 RD_Data_logger_Global_Header_Field — (1 of 256, stride 16)
  [31:0] global_hdr — Current value of the Global Header field.
0xA004 RD_Data_logger_TM_Software_Timestamp — (1 of 256, stride 16)
  [31:0] tm_sw_timestamp — Current value of the TM software timestamp.
0xA008 RD_Data_logger_HW_Timestamp_and_Engine_Errors — (1 of 256, stride 16)
  [31:24] eng_err — Current value of the TM engine errors.
  [23:0] tm_hw_timestamp — Current value of the RD Hardware Timestamp.
0xB000 COR_Data_logger_Global_Header_Field — (1 of 256, stride 16)
  [31:0] global_hdr — Current value of the Global Header field.
0xB004 COR_Data_logger_TM_Software_Timestamp — (1 of 256, stride 16)
  [31:0] tm_sw_timestamp — Current value of the TM software timestamp.
0xB008 COR_Data_logger_HW_Timestamp_and_Engine_Errors — (1 of 256, stride 16)
  [31:24] eng_err — Current value of the COR engine errors.
  [23:0] tm_hw_timestamp — Current value of the TM Hardware Timestamp.
0xC000 CRC_Data_logger_Global_Header_Field — (1 of 256, stride 16)
  [31:0] global_hdr — Current value of the Global Header field.
0xC004 CRC_Data_logger_TM_Software_Timestamp — (1 of 256, stride 16)
  [31:0] tm_sw_timestamp — Current value of the TM software timestamp.
0xC008 CRC_Data_logger_HW_Timestamp_and_Engine_Errors — (1 of 256, stride 16)
  [31:25] eng_err — Current value of the CRC engine errors.
  [24] ppb_err — Current value of the CRC engine errors.
  [23:0] tm_hw_timestamp — Current value of the TM Hardware Timestamp.
